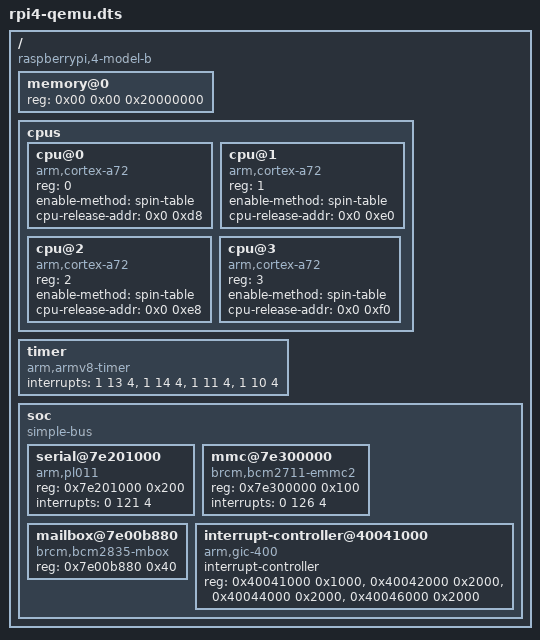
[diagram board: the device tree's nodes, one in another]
/dts-v1/;

/* A small device tree for qemu's "raspi4b" machine. qemu does not create one (the real Raspberry Pi firmware does; the kernel
 * reads that one on the board). It is laid out like the real tree of the BCM2711 (bcm2711.dtsi): the devices sit on the bus
 * "soc" and are given with *bus addresses* (the UART at 0x7e201000, the GIC at 0x40041000); the "ranges" of the bus translate
 * them to the addresses the ARM cores use (0xfe201000, 0xff841000). dt.c has to do that translation, so this tree tests it. */

/ {
	compatible = "raspberrypi,4-model-b", "brcm,bcm2711";
	#address-cells = <2>;
	#size-cells = <1>;

	memory@0 {
		device_type = "memory";
		reg = <0x00 0x00 0x20000000>;           /* qemu fills in the real size */
	};

	cpus {
		#address-cells = <1>;
		#size-cells = <0>;
		cpu@0 {
			device_type = "cpu";
			compatible = "arm,cortex-a72";
			reg = <0>;
			enable-method = "spin-table";
			cpu-release-addr = <0x0 0xd8>;
		};
		cpu@1 {
			device_type = "cpu";
			compatible = "arm,cortex-a72";
			reg = <1>;
			enable-method = "spin-table";
			cpu-release-addr = <0x0 0xe0>;
		};
		cpu@2 {
			device_type = "cpu";
			compatible = "arm,cortex-a72";
			reg = <2>;
			enable-method = "spin-table";
			cpu-release-addr = <0x0 0xe8>;
		};
		cpu@3 {
			device_type = "cpu";
			compatible = "arm,cortex-a72";
			reg = <3>;
			enable-method = "spin-table";
			cpu-release-addr = <0x0 0xf0>;
		};
	};

	timer {
		compatible = "arm,armv8-timer";
		interrupts = <1 13 4>, <1 14 4>, <1 11 4>, <1 10 4>;
	};

	soc {
		compatible = "simple-bus";
		#address-cells = <1>;
		#size-cells = <1>;
		/* bus address, address in the address space of the cores, size */
		ranges = <0x7e000000  0x00 0xfe000000  0x01800000>,
			 <0x7c000000  0x00 0xfc000000  0x02000000>,
			 <0x40000000  0x00 0xff800000  0x00800000>;

		serial@7e201000 {
			compatible = "arm,pl011", "arm,primecell";
			reg = <0x7e201000 0x200>;
			interrupts = <0 121 4>;
		};

		/* qemu puts the SD card on the controller at 0x7e300000. On the real board the card slot is EMMC2 at 0x7e340000: the
		 * firmware's tree says so, and that is the address the kernel then uses. */
		mmc@7e300000 {
			compatible = "brcm,bcm2711-emmc2";
			reg = <0x7e300000 0x100>;
			interrupts = <0 126 4>;
		};

		/* the mailbox of the VideoCore: the frame buffer of the HDMI console is asked for here (chapter "Screen") */
		mailbox@7e00b880 {
			compatible = "brcm,bcm2835-mbox";
			reg = <0x7e00b880 0x40>;
		};

		interrupt-controller@40041000 {
			compatible = "arm,gic-400", "arm,cortex-a15-gic";
			#interrupt-cells = <3>;
			interrupt-controller;
			reg = <0x40041000 0x1000>, <0x40042000 0x2000>,
			      <0x40044000 0x2000>, <0x40046000 0x2000>;
		};
	};
};
